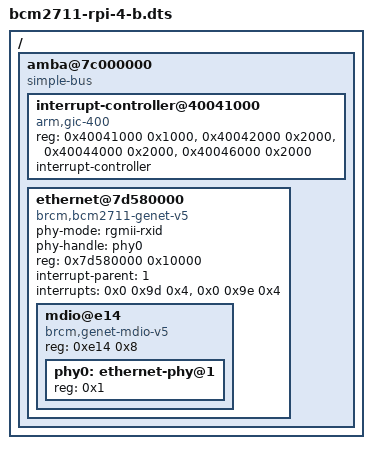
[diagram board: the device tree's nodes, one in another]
/* SPDX-License-Identifier: BSD-2-Clause */

/**
 * @file
 *
 * @ingroup RTEMSBSPsAArch64Raspberrypi4
 *
 * @brief This file provides the base Raspberrypi4 device tree
 */

/*
 * Copyright (C) 2024 Ning Yang
 *
 * Redistribution and use in source and binary forms, with or without
 * modification, are permitted provided that the following conditions
 * are met:
 * 1. Redistributions of source code must retain the above copyright
 *    notice, this list of conditions and the following disclaimer.
 * 2. Redistributions in binary form must reproduce the above copyright
 *    notice, this list of conditions and the following disclaimer in the
 *    documentation and/or other materials provided with the distribution.
 *
 * THIS SOFTWARE IS PROVIDED BY THE COPYRIGHT HOLDERS AND CONTRIBUTORS "AS IS"
 * AND ANY EXPRESS OR IMPLIED WARRANTIES, INCLUDING, BUT NOT LIMITED TO, THE
 * IMPLIED WARRANTIES OF MERCHANTABILITY AND FITNESS FOR A PARTICULAR PURPOSE
 * ARE DISCLAIMED. IN NO EVENT SHALL THE COPYRIGHT OWNER OR CONTRIBUTORS BE
 * LIABLE FOR ANY DIRECT, INDIRECT, INCIDENTAL, SPECIAL, EXEMPLARY, OR
 * CONSEQUENTIAL DAMAGES (INCLUDING, BUT NOT LIMITED TO, PROCUREMENT OF
 * SUBSTITUTE GOODS OR SERVICES; LOSS OF USE, DATA, OR PROFITS; OR BUSINESS
 * INTERRUPTION) HOWEVER CAUSED AND ON ANY THEORY OF LIABILITY, WHETHER IN
 * CONTRACT, STRICT LIABILITY, OR TORT (INCLUDING NEGLIGENCE OR OTHERWISE)
 * ARISING IN ANY WAY OUT OF THE USE OF THIS SOFTWARE, EVEN IF ADVISED OF THE
 * POSSIBILITY OF SUCH DAMAGE.
 */

/dts-v1/;

/ {
	#address-cells = <2>;
	#size-cells = <1>;

	amba@7c000000 {
		compatible = "simple-bus";
		#address-cells = <1>;
		#size-cells = <1>;
		ranges = <0x7c000000 0x00 0xfc000000 0x3800000>, <0x40000000 0x00 0xff800000 0x800000>;

		interrupt-controller@40041000 {
			compatible = "arm,gic-400";
			#address-cells = <2>;
			#interrupt-cells = <3>;
			reg = <0x40041000 0x1000>, <0x40042000 0x2000>, <0x40044000 0x2000>, <0x40046000 0x2000>;
			interrupt-controller;
			phandle = <1>;
		};

		ethernet@7d580000 {
			phy-mode = "rgmii-rxid";
			phy-handle = <&phy0>;
			compatible = "brcm,bcm2711-genet-v5";
			#address-cells = <1>;
			#size-cells = <1>;
			reg = <0x7d580000 0x10000>;
			interrupt-parent = <1>;
			interrupts = <0x0 0x9d 0x4> , <0x0 0x9e 0x4>;

			mdio@e14 {
				compatible = "brcm,genet-mdio-v5";
				#address-cells = <1>;
				#size-cells = <0>;
				reg = <0xe14 0x8>;

				phy0: ethernet-phy@1 {
					reg = <0x1>;
				};
			};
		};
	};
};
